VERSION ""

NS_ :

BS_:

BU_: DISPLAY GEAR INDICATOR SYSTEM

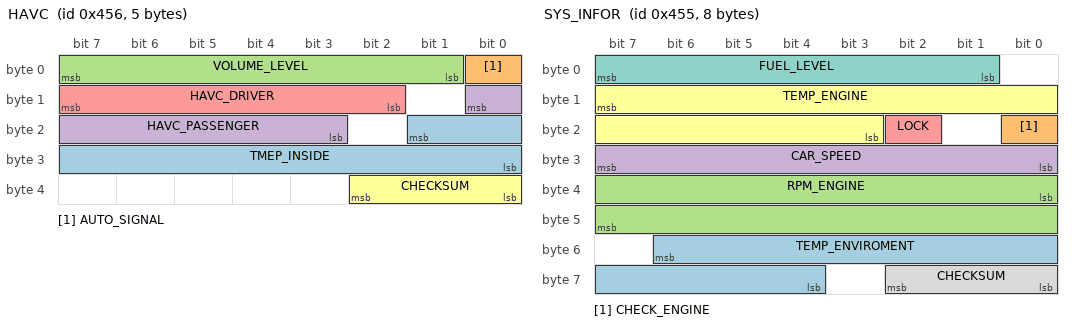
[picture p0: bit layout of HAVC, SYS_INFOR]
BO_ 1110 HAVC: 5 SYSTEM
 SG_ TMEP_INSIDE : 17|10@0- (0.1,-5) [-5|52.1] "degree c"  DISPLAY
 SG_ AUTO_SIGNAL : 0|1@0+ (1,0) [0|1] ""  DISPLAY
 SG_ VOLUME_LEVEL : 7|7@0+ (1,0) [0|100] "%"  DISPLAY
 SG_ HAVC_PASSENGER : 8|6@0+ (1,0) [0|50] "degree c"  DISPLAY
 SG_ HAVC_DRIVER : 15|6@0+ (1,0) [0|50] "degree c"  DISPLAY
 SG_ CHECKSUM : 34|3@0+ (1,0) [0|3] ""  DISPLAY

BO_ 1109 SYS_INFOR: 8 SYSTEM
 SG_ TEMP_ENVIROMENT : 54|11@0- (0.1,-40) [-40|102.3] ""  DISPLAY
 SG_ CHECK_ENGINE : 16|1@0+ (1,0) [0|1] ""  DISPLAY
 SG_ RPM_ENGINE : 32|16@1+ (1,0) [0|65535] "rpm"  DISPLAY
 SG_ CAR_SPEED : 24|8@1+ (1,0) [0|255] "kph"  DISPLAY
 SG_ LOCK : 18|1@0+ (1,0) [0|1] ""  DISPLAY
 SG_ TEMP_ENGINE : 15|13@0- (0.1,-10) [-10|409.5] "degree c"  DISPLAY
 SG_ FUEL_LEVEL : 7|7@0+ (1,0) [0|100] "%"  DISPLAY
 SG_ CHECKSUM : 58|3@0+ (1,0) [0|3] ""  DISPLAY

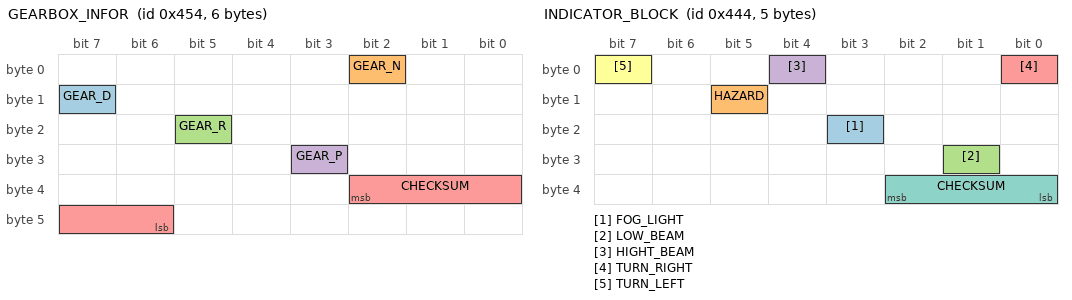
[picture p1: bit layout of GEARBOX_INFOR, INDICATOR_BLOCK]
BO_ 1108 GEARBOX_INFOR: 6 GEAR
 SG_ GEAR_D : 15|1@0+ (1,0) [0|1] ""  DISPLAY
 SG_ GEAR_N : 2|1@0+ (1,0) [0|1] ""  DISPLAY
 SG_ GEAR_R : 21|1@0+ (1,0) [0|1] ""  DISPLAY
 SG_ GEAR_P : 27|1@0+ (1,0) [0|1] ""  DISPLAY
 SG_ CHECKSUM : 34|5@0+ (1,0) [0|15] ""  DISPLAY

BO_ 1092 INDICATOR_BLOCK: 5 INDICATOR
 SG_ FOG_LIGHT : 19|1@0+ (1,0) [0|1] ""  DISPLAY
 SG_ HAZARD : 13|1@0+ (1,0) [0|1] ""  DISPLAY
 SG_ LOW_BEAM : 25|1@0+ (1,0) [0|1] ""  DISPLAY
 SG_ HIGHT_BEAM : 4|1@0+ (1,0) [0|1] ""  DISPLAY
 SG_ TURN_RIGHT : 0|1@0+ (1,0) [0|1] ""  DISPLAY
 SG_ TURN_LEFT : 7|1@0+ (1,0) [0|1] ""  DISPLAY
 SG_ CHECKSUM : 34|3@0+ (1,0) [0|3] ""  DISPLAY

CM_ BU_ INDICATOR "Containt: turn signal, light signal, hazal signal";
CM_ BU_ SYSTEM "Containt: fuel level, temperature engin, temp enviroment, lock- unpock car door, check engine inditator";
